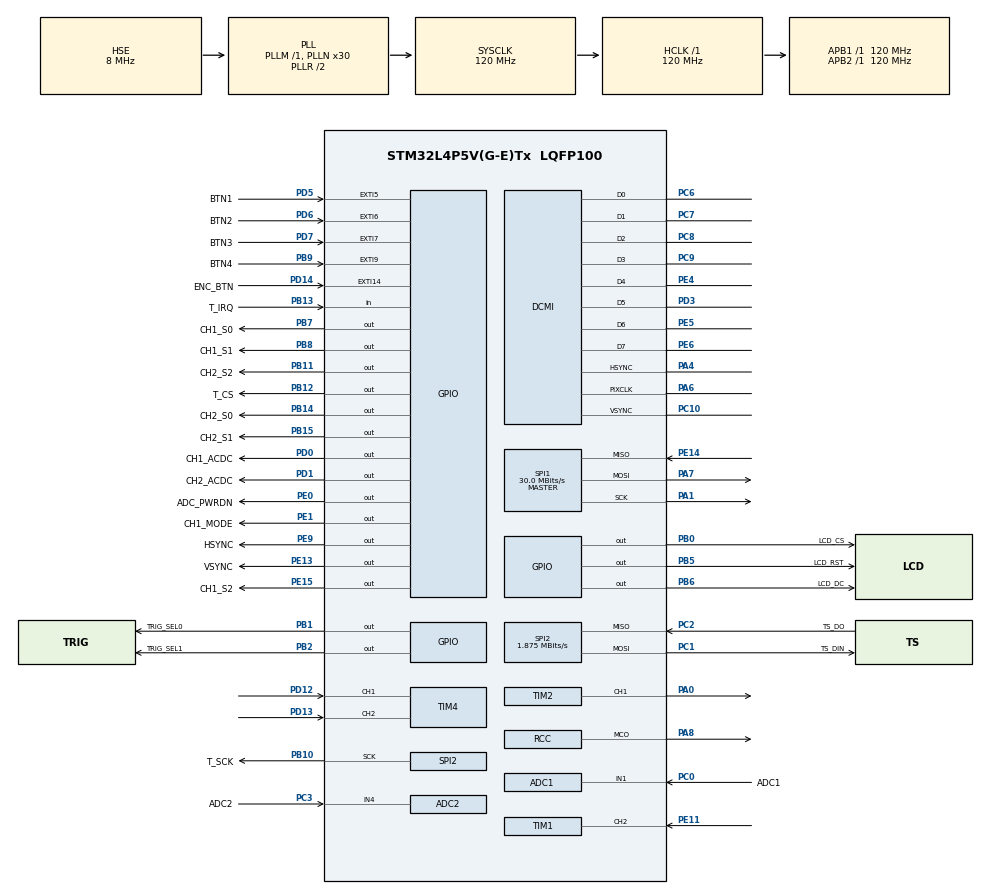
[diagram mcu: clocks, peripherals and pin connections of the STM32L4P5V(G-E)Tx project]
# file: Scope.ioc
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ADC1.Channel-0\#ChannelRegularConversion=ADC_CHANNEL_1
ADC1.ClockPrescaler=ADC_CLOCK_ASYNC_DIV2
ADC1.ContinuousConvMode=ENABLE
ADC1.DMAContinuousRequests=ENABLE
ADC1.NbrOfConversionFlag=1
ADC1.OffsetNumber-0\#ChannelRegularConversion=ADC_OFFSET_NONE
ADC1.Rank-0\#ChannelRegularConversion=1
ADC1.Resolution=ADC_RESOLUTION_8B
ADC1.SamplingTime-0\#ChannelRegularConversion=ADC_SAMPLETIME_2CYCLES_5
ADC1.master=1
ADC2.Channel-0\#ChannelRegularConversion=ADC_CHANNEL_4
ADC2.ContinuousConvMode=ENABLE
ADC2.DMAContinuousRequests=ENABLE
ADC2.ExternalTrigConv=ADC_SOFTWARE_START
ADC2.NbrOfConversionFlag=1
ADC2.OffsetNumber-0\#ChannelRegularConversion=ADC_OFFSET_NONE
ADC2.Rank-0\#ChannelRegularConversion=1
ADC2.Resolution=ADC_RESOLUTION_8B
ADC2.SamplingTime-0\#ChannelRegularConversion=ADC_SAMPLETIME_2CYCLES_5
DCMI.ByteSelectMode=DCMI_BSM_ALL
DCMI.CaptureRate=DCMI_CR_ALL_FRAME
DCMI.HSPolarity=DCMI_HSPOLARITY_HIGH
DCMI.JPEGMode=DCMI_JPEG_DISABLE
DCMI.PCKPolarity=DCMI_PCKPOLARITY_FALLING
DCMI.VSPolarity=DCMI_VSPOLARITY_HIGH
Dma.ADC1.2.Direction=DMA_PERIPH_TO_MEMORY
Dma.ADC1.2.EventEnable=DISABLE
Dma.ADC1.2.Instance=DMA1_Channel3
Dma.ADC1.2.MemDataAlignment=DMA_MDATAALIGN_BYTE
Dma.ADC1.2.MemInc=DMA_MINC_ENABLE
Dma.ADC1.2.Mode=DMA_NORMAL
Dma.ADC1.2.PeriphDataAlignment=DMA_PDATAALIGN_BYTE
Dma.ADC1.2.PeriphInc=DMA_PINC_DISABLE
Dma.ADC1.2.Polarity=HAL_DMAMUX_REQ_GEN_RISING
Dma.ADC1.2.Priority=DMA_PRIORITY_HIGH
Dma.ADC1.2.RequestNumber=1
Dma.ADC1.2.SignalID=NONE
Dma.ADC1.2.SyncEnable=DISABLE
Dma.ADC1.2.SyncPolarity=HAL_DMAMUX_SYNC_NO_EVENT
Dma.ADC1.2.SyncRequestNumber=1
Dma.ADC1.2.SyncSignalID=NONE
Dma.ADC2.0.Direction=DMA_PERIPH_TO_MEMORY
Dma.ADC2.0.EventEnable=DISABLE
Dma.ADC2.0.Instance=DMA1_Channel1
Dma.ADC2.0.MemDataAlignment=DMA_MDATAALIGN_BYTE
Dma.ADC2.0.MemInc=DMA_MINC_ENABLE
Dma.ADC2.0.Mode=DMA_NORMAL
Dma.ADC2.0.PeriphDataAlignment=DMA_PDATAALIGN_BYTE
Dma.ADC2.0.PeriphInc=DMA_PINC_DISABLE
Dma.ADC2.0.Polarity=HAL_DMAMUX_REQ_GEN_RISING
Dma.ADC2.0.Priority=DMA_PRIORITY_HIGH
Dma.ADC2.0.RequestNumber=1
Dma.ADC2.0.SignalID=NONE
Dma.ADC2.0.SyncEnable=DISABLE
Dma.ADC2.0.SyncPolarity=HAL_DMAMUX_SYNC_NO_EVENT
Dma.ADC2.0.SyncRequestNumber=1
Dma.ADC2.0.SyncSignalID=NONE
Dma.DCMI.3.Direction=DMA_PERIPH_TO_MEMORY
Dma.DCMI.3.EventEnable=DISABLE
Dma.DCMI.3.Instance=DMA2_Channel1
Dma.DCMI.3.MemDataAlignment=DMA_MDATAALIGN_WORD
Dma.DCMI.3.MemInc=DMA_MINC_ENABLE
Dma.DCMI.3.Mode=DMA_NORMAL
Dma.DCMI.3.PeriphDataAlignment=DMA_PDATAALIGN_WORD
Dma.DCMI.3.PeriphInc=DMA_PINC_DISABLE
Dma.DCMI.3.Polarity=HAL_DMAMUX_REQ_GEN_RISING
Dma.DCMI.3.Priority=DMA_PRIORITY_HIGH
Dma.DCMI.3.RequestNumber=1
Dma.DCMI.3.SignalID=NONE
Dma.DCMI.3.SyncEnable=DISABLE
Dma.DCMI.3.SyncPolarity=HAL_DMAMUX_SYNC_NO_EVENT
Dma.DCMI.3.SyncRequestNumber=1
Dma.DCMI.3.SyncSignalID=NONE
Dma.Request0=ADC2
Dma.Request1=SPI1_TX
Dma.Request2=ADC1
Dma.Request3=DCMI
Dma.SPI1_TX.1.Direction=DMA_MEMORY_TO_PERIPH
Dma.SPI1_TX.1.EventEnable=DISABLE
Dma.SPI1_TX.1.Instance=DMA1_Channel2
Dma.SPI1_TX.1.MemDataAlignment=DMA_MDATAALIGN_BYTE
Dma.SPI1_TX.1.MemInc=DMA_MINC_ENABLE
Dma.SPI1_TX.1.Mode=DMA_NORMAL
Dma.SPI1_TX.1.PeriphDataAlignment=DMA_PDATAALIGN_BYTE
Dma.SPI1_TX.1.PeriphInc=DMA_PINC_DISABLE
Dma.SPI1_TX.1.Polarity=HAL_DMAMUX_REQ_GEN_RISING
Dma.SPI1_TX.1.Priority=DMA_PRIORITY_MEDIUM
Dma.SPI1_TX.1.RequestNumber=1
Dma.SPI1_TX.1.SignalID=NONE
Dma.SPI1_TX.1.SyncEnable=DISABLE
Dma.SPI1_TX.1.SyncPolarity=HAL_DMAMUX_SYNC_NO_EVENT
Dma.SPI1_TX.1.SyncRequestNumber=1
Dma.SPI1_TX.1.SyncSignalID=NONE
Mcu.Family=STM32L4
Mcu.Name=STM32L4P5V(G-E)Tx
Mcu.Package=LQFP100
NVIC.ADC1_2_IRQn=true\:0\:0\:false\:false\:true\:true\:true
NVIC.DMA1_Channel1_IRQn=true\:0\:0\:false\:false\:true\:false\:true
NVIC.DMA1_Channel2_IRQn=true\:0\:0\:false\:false\:true\:false\:true
NVIC.DMA1_Channel3_IRQn=true\:0\:0\:false\:false\:true\:false\:true
NVIC.DMA2_Channel1_IRQn=true\:0\:0\:false\:false\:true\:false\:true
NVIC.EXTI15_10_IRQn=true\:0\:0\:false\:false\:true\:true\:true
NVIC.EXTI9_5_IRQn=true\:0\:0\:false\:false\:true\:true\:true
NVIC.PriorityGroup=NVIC_PRIORITYGROUP_4
NVIC.SPI1_IRQn=true\:0\:0\:false\:false\:true\:true\:true
NVIC.TIM1_CC_IRQn=true\:0\:0\:false\:false\:true\:true\:true
PA0.GPIO_Speed=GPIO_SPEED_FREQ_VERY_HIGH
PA0.Signal=S_TIM2_CH1
PA1.Mode=Full_Duplex_Master
PA1.Signal=SPI1_SCK
PA13\ (JTMS/SWDIO).Mode=Serial_Wire
PA13\ (JTMS/SWDIO).Signal=SYS_JTMS-SWDIO
PA14\ (JTCK/SWCLK).Mode=Serial_Wire
PA14\ (JTCK/SWCLK).Signal=SYS_JTCK-SWCLK
PA4.GPIO_Speed=GPIO_SPEED_FREQ_VERY_HIGH
PA4.Mode=Slave_8_bits_External_Synchro
PA4.Signal=DCMI_HSYNC
PA6.GPIO_Speed=GPIO_SPEED_FREQ_VERY_HIGH
PA6.Mode=Slave_8_bits_External_Synchro
PA6.Signal=DCMI_PIXCLK
PA7.Mode=Full_Duplex_Master
PA7.Signal=SPI1_MOSI
PA8.GPIO_PuPd=GPIO_NOPULL
PA8.GPIO_Speed=GPIO_SPEED_FREQ_VERY_HIGH
PA8.Mode=Clock-out
PA8.Signal=RCC_MCO
PB0.GPIO_Label=LCD_CS
PB0.GPIO_Speed=GPIO_SPEED_FREQ_VERY_HIGH
PB0.Signal=GPIO_Output
PB1.GPIO_Label=TRIG_SEL0
PB1.Signal=GPIO_Output
PB10.GPIO_Label=T_SCK
PB10.Mode=Full_Duplex_Master
PB10.Signal=SPI2_SCK
PB11.GPIO_Label=CH2_S2
PB11.Signal=GPIO_Output
PB12.GPIO_Label=T_CS
PB12.GPIO_Speed=GPIO_SPEED_FREQ_VERY_HIGH
PB12.Signal=GPIO_Output
PB13.GPIO_Label=T_IRQ
PB13.Signal=GPIO_Input
PB14.GPIO_Label=CH2_S0
PB14.Signal=GPIO_Output
PB15.GPIO_Label=CH2_S1
PB15.Signal=GPIO_Output
PB2.GPIO_Label=TRIG_SEL1
PB2.Signal=GPIO_Output
PB5.GPIO_Label=LCD_RST
PB5.GPIO_Speed=GPIO_SPEED_FREQ_VERY_HIGH
PB5.Signal=GPIO_Output
PB6.GPIO_FM6=__NULL
PB6.GPIO_Label=LCD_DC
PB6.GPIO_Speed=GPIO_SPEED_FREQ_VERY_HIGH
PB6.Signal=GPIO_Output
PB7.GPIO_Label=CH1_S0
PB7.Signal=GPIO_Output
PB8.GPIO_Label=CH1_S1
PB8.Signal=GPIO_Output
PB9.GPIO_Label=BTN4
PB9.GPIO_ModeDefaultEXTI=GPIO_MODE_IT_RISING_FALLING
PB9.GPIO_PuPd=GPIO_PULLDOWN
PB9.Signal=GPXTI9
PC0.GPIO_Label=ADC1
PC0.Signal=ADCx_IN1
PC1.GPIO_Label=TS_DIN
PC1.Mode=Full_Duplex_Master
PC1.Signal=SPI2_MOSI
PC10.GPIO_Speed=GPIO_SPEED_FREQ_VERY_HIGH
PC10.Mode=Slave_8_bits_External_Synchro
PC10.Signal=DCMI_VSYNC
PC2.GPIO_Label=TS_DO
PC2.Mode=Full_Duplex_Master
PC2.Signal=SPI2_MISO
PC3.GPIO_Label=ADC2
PC3.Signal=ADCx_IN4
PC6.GPIO_Speed=GPIO_SPEED_FREQ_VERY_HIGH
PC6.Mode=Slave_8_bits_External_Synchro
PC6.Signal=DCMI_D0
PC7.GPIO_Speed=GPIO_SPEED_FREQ_VERY_HIGH
PC7.Mode=Slave_8_bits_External_Synchro
PC7.Signal=DCMI_D1
PC8.GPIO_Speed=GPIO_SPEED_FREQ_VERY_HIGH
PC8.Mode=Slave_8_bits_External_Synchro
PC8.Signal=DCMI_D2
PC9.GPIO_Speed=GPIO_SPEED_FREQ_VERY_HIGH
PC9.Mode=Slave_8_bits_External_Synchro
PC9.Signal=DCMI_D3
PD0.GPIO_Label=CH1_ACDC
PD0.Signal=GPIO_Output
PD1.GPIO_Label=CH2_ACDC
PD1.Signal=GPIO_Output
PD12.Signal=S_TIM4_CH1
PD13.Signal=S_TIM4_CH2
PD14.GPIO_Label=ENC_BTN
PD14.GPIO_ModeDefaultEXTI=GPIO_MODE_IT_RISING_FALLING
PD14.GPIO_PuPd=GPIO_PULLDOWN
PD14.Signal=GPXTI14
PD3.GPIO_Speed=GPIO_SPEED_FREQ_VERY_HIGH
PD3.Mode=Slave_8_bits_External_Synchro
PD3.Signal=DCMI_D5
PD5.GPIO_Label=BTN1
PD5.GPIO_ModeDefaultEXTI=GPIO_MODE_IT_RISING_FALLING
PD5.GPIO_PuPd=GPIO_PULLDOWN
PD5.Signal=GPXTI5
PD6.GPIO_Label=BTN2
PD6.GPIO_ModeDefaultEXTI=GPIO_MODE_IT_RISING_FALLING
PD6.GPIO_PuPd=GPIO_PULLDOWN
PD6.Signal=GPXTI6
PD7.GPIO_Label=BTN3
PD7.GPIO_ModeDefaultEXTI=GPIO_MODE_IT_RISING_FALLING
PD7.GPIO_PuPd=GPIO_PULLDOWN
PD7.Signal=GPXTI7
PE0.GPIO_Label=ADC_PWRDN
PE0.Signal=GPIO_Output
PE1.GPIO_Label=CH1_MODE
PE1.Signal=GPIO_Output
PE11.GPIO_Speed=GPIO_SPEED_FREQ_VERY_HIGH
PE11.Signal=S_TIM1_CH2
PE13.GPIO_Label=VSYNC
PE13.GPIO_Speed=GPIO_SPEED_FREQ_VERY_HIGH
PE13.Signal=GPIO_Output
PE14.Mode=Full_Duplex_Master
PE14.Signal=SPI1_MISO
PE15.GPIO_Label=CH1_S2
PE15.Signal=GPIO_Output
PE4.GPIO_Speed=GPIO_SPEED_FREQ_VERY_HIGH
PE4.Mode=Slave_8_bits_External_Synchro
PE4.Signal=DCMI_D4
PE5.GPIO_Speed=GPIO_SPEED_FREQ_VERY_HIGH
PE5.Mode=Slave_8_bits_External_Synchro
PE5.Signal=DCMI_D6
PE6.GPIO_Speed=GPIO_SPEED_FREQ_VERY_HIGH
PE6.Mode=Slave_8_bits_External_Synchro
PE6.Signal=DCMI_D7
PE9.GPIO_Label=HSYNC
PE9.GPIO_Speed=GPIO_SPEED_FREQ_VERY_HIGH
PE9.Signal=GPIO_Output
PH0-OSC_IN\ (PH0).Mode=HSE-External-Oscillator
PH0-OSC_IN\ (PH0).Signal=RCC_OSC_IN
PH1-OSC_OUT\ (PH1).Mode=HSE-External-Oscillator
PH1-OSC_OUT\ (PH1).Signal=RCC_OSC_OUT
ProjectManager.HeapSize=0x200
ProjectManager.StackSize=0x400
ProjectManager.TargetToolchain=STM32CubeIDE
RCC.ADCCLockSelection=RCC_ADCCLKSOURCE_SYSCLK
RCC.ADCFreq_Value=120000000
RCC.AHBFreq_Value=120000000
RCC.APB1Freq_Value=120000000
RCC.APB1TimFreq_Value=120000000
RCC.APB2Freq_Value=120000000
RCC.APB2TimFreq_Value=120000000
RCC.CortexFreq_Value=120000000
RCC.HCLKFreq_Value=120000000
RCC.HSE_VALUE=8000000
RCC.HSI48_VALUE=48000000
RCC.HSI_VALUE=16000000
RCC.LSE_VALUE=32768
RCC.MSI_VALUE=4000000
RCC.PLLN=30
RCC.PLLSAI1N=12
RCC.PLLSourceVirtual=RCC_PLLSOURCE_HSE
RCC.RCC_MCO1Source=RCC_MCO1SOURCE_HSI48
RCC.SYSCLKFreq_VALUE=120000000
RCC.SYSCLKSource=RCC_SYSCLKSOURCE_PLLCLK
RCC.USBFreq_Value=48000000
RCC.VCOOutputFreq_Value=240000000
SH.ADCx_IN1.0=ADC1_IN1,IN1-Single-Ended
SH.ADCx_IN4.0=ADC2_IN4,IN4-Single-Ended
SH.S_TIM1_CH2.0=TIM1_CH2,Input_Capture2_from_TI2
SH.S_TIM1_CH2.1=TIM1_CH2,TriggerSource_TI2FP2
SH.S_TIM2_CH1.0=TIM2_CH1,PWM Generation1 CH1
SH.S_TIM4_CH1.0=TIM4_CH1,Encoder_Interface
SH.S_TIM4_CH2.0=TIM4_CH2,Encoder_Interface
SPI1.BaudRatePrescaler=SPI_BAUDRATEPRESCALER_4
SPI1.CalculateBaudRate=30.0 MBits/s
SPI1.DataSize=SPI_DATASIZE_8BIT
SPI1.Direction=SPI_DIRECTION_2LINES
SPI1.Mode=SPI_MODE_MASTER
SPI1.VirtualType=VM_MASTER
SPI2.BaudRatePrescaler=SPI_BAUDRATEPRESCALER_64
SPI2.CalculateBaudRate=1.875 MBits/s
SPI2.DataSize=SPI_DATASIZE_8BIT
SPI2.Direction=SPI_DIRECTION_2LINES
SPI2.Mode=SPI_MODE_MASTER
SPI2.VirtualType=VM_MASTER
TIM1.AutoReloadPreload=TIM_AUTORELOAD_PRELOAD_DISABLE
TIM1.Channel-Input_Capture2_from_TI2=TIM_CHANNEL_2
TIM1.Channel-PWM\ Generation1\ CH1=TIM_CHANNEL_1
TIM1.ICFilter_CH2=0
TIM1.ICPolarity_CH2=TIM_INPUTCHANNELPOLARITY_FALLING
TIM1.OCMode_PWM-PWM\ Generation1\ CH1=TIM_OCMODE_PWM1
TIM1.Period=0xffff-1
TIM1.Prescaler=0
TIM1.Pulse-PWM\ Generation1\ CH1=1
TIM1.TIM_MasterOutputTrigger=TIM_TRGO_UPDATE
TIM1.TIM_MasterSlaveMode=TIM_MASTERSLAVEMODE_DISABLE
TIM2.Channel-PWM\ Generation1\ CH1=TIM_CHANNEL_1
TIM2.Period=99
TIM2.Prescaler=120
VP_TIM1_VS_ControllerModeReset.Mode=Reset Mode
board=custom

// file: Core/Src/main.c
/* USER CODE BEGIN Header */
/**
  ******************************************************************************
  * @file           : main.c
  * @brief          : Main program body
  ******************************************************************************
  * @attention
  *
  * <h2><center>&copy; Copyright (c) 2020 STMicroelectronics.
  * All rights reserved.</center></h2>
  *
  * This software component is licensed by ST under BSD 3-Clause license,
  * the "License"; You may not use this file except in compliance with the
  * License. You may obtain a copy of the License at:
  *                        opensource.org/licenses/BSD-3-Clause
  *
  ******************************************************************************
  */
/* USER CODE END Header */
#include "main.h"
#include "adc.h"
#include "dcmi.h"
#include "dma.h"
#include "spi.h"
#include "tim.h"
#include "gpio.h"

/* USER CODE BEGIN Includes */
#include "mainloop.h"

/* USER CODE END Includes */

void SystemClock_Config(void);

int main(void)
{

  /* MCU Configuration--------------------------------------------------------*/

  /* Reset of all peripherals, Initializes the Flash interface and the Systick. */
  HAL_Init();

  /* Configure the system clock */
  SystemClock_Config();

  /* Initialize all configured peripherals */
  MX_GPIO_Init();
  MX_DMA_Init();
  MX_ADC1_Init();
  MX_ADC2_Init();
  MX_DCMI_Init();
  MX_SPI1_Init();
  MX_SPI2_Init();
  MX_TIM1_Init();
  MX_TIM2_Init();
  MX_TIM4_Init();
  /* USER CODE BEGIN 2 */

  scope_run();

  /* USER CODE END 2 */

  /* Infinite loop */
  while (1)
  {

  }
}

void SystemClock_Config(void)
{
  RCC_OscInitTypeDef RCC_OscInitStruct = {0};
  RCC_ClkInitTypeDef RCC_ClkInitStruct = {0};
  RCC_PeriphCLKInitTypeDef PeriphClkInit = {0};

  /** Configure the main internal regulator output voltage
  */
  if (HAL_PWREx_ControlVoltageScaling(PWR_REGULATOR_VOLTAGE_SCALE1_BOOST) != HAL_OK)
  {
    Error_Handler();
  }
  /** Initializes the RCC Oscillators according to the specified parameters
  * in the RCC_OscInitTypeDef structure.
  */
  RCC_OscInitStruct.OscillatorType = RCC_OSCILLATORTYPE_HSI48|RCC_OSCILLATORTYPE_HSE;
  RCC_OscInitStruct.HSEState = RCC_HSE_ON;
  RCC_OscInitStruct.HSI48State = RCC_HSI48_ON;
  RCC_OscInitStruct.PLL.PLLState = RCC_PLL_ON;
  RCC_OscInitStruct.PLL.PLLSource = RCC_PLLSOURCE_HSE;
  RCC_OscInitStruct.PLL.PLLM = 1;
  RCC_OscInitStruct.PLL.PLLN = 30;
  RCC_OscInitStruct.PLL.PLLP = RCC_PLLP_DIV7;
  RCC_OscInitStruct.PLL.PLLQ = RCC_PLLQ_DIV2;
  RCC_OscInitStruct.PLL.PLLR = RCC_PLLR_DIV2;
  if (HAL_RCC_OscConfig(&RCC_OscInitStruct) != HAL_OK)
  {
    Error_Handler();
  }
  /** Initializes the CPU, AHB and APB buses clocks
  */
  RCC_ClkInitStruct.ClockType = RCC_CLOCKTYPE_HCLK|RCC_CLOCKTYPE_SYSCLK
                              |RCC_CLOCKTYPE_PCLK1|RCC_CLOCKTYPE_PCLK2;
  RCC_ClkInitStruct.SYSCLKSource = RCC_SYSCLKSOURCE_PLLCLK;
  RCC_ClkInitStruct.AHBCLKDivider = RCC_SYSCLK_DIV1;
  RCC_ClkInitStruct.APB1CLKDivider = RCC_HCLK_DIV1;
  RCC_ClkInitStruct.APB2CLKDivider = RCC_HCLK_DIV1;

  if (HAL_RCC_ClockConfig(&RCC_ClkInitStruct, FLASH_LATENCY_5) != HAL_OK)
  {
    Error_Handler();
  }
  PeriphClkInit.PeriphClockSelection = RCC_PERIPHCLK_ADC;
  PeriphClkInit.AdcClockSelection = RCC_ADCCLKSOURCE_SYSCLK;
  if (HAL_RCCEx_PeriphCLKConfig(&PeriphClkInit) != HAL_OK)
  {
    Error_Handler();
  }
  HAL_RCC_MCOConfig(RCC_MCO1, RCC_MCO1SOURCE_HSI48, RCC_MCODIV_1);
}

void Error_Handler(void)
{
}

/************************ (C) COPYRIGHT STMicroelectronics *****END OF FILE****/
